# STM32G534xx register map
File version: 1.0
Registers are 32-bit, read-write, reset 0x0 unless marked. A register's access mark holds for its fields unless they carry their own. Offsets are from the block's base; [hi:lo] are bit positions; {n}, {i} and the like mark numbered series; 'fields as' and 'values as' point back to an identical list.

## VREFBUF — Voltage reference buffer (VREFBUF)
Base 0x44007400
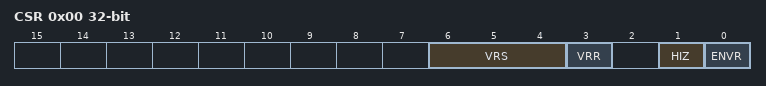
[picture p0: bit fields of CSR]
0x00 CSR — VREFBUF control and status register
  [6:4] VRS — Voltage reference scale
  [3] VRR — Voltage reference buffer ready
  [1] HIZ — High impedance mode
  [0] ENVR — Voltage reference buffer mode enable
0x04 CCR — VREFBUF calibration control register
  [5:0] TRIM — Trimming code

## COMP12_COMMON
Base 0x44008400
Same registers: COMP34_COMMON 0x44008C00, COMP56_COMMON 0x44009400, COMP78_COMMON 0x44009C00
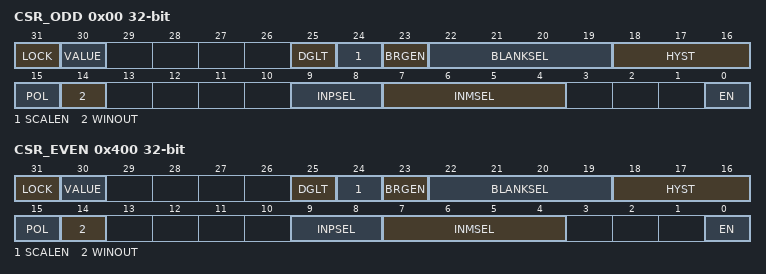
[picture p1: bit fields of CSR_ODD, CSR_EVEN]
0x00 CSR_ODD — COMP control and status register located in register of comparator instance odd, used for bits common to several COMP instances
  [31] LOCK
  [30] VALUE — COMPx output value
  [25] DGLT — DEGLITCHER enable
  [24] SCALEN — VREFINT scaler enable
  [23] BRGEN — VREFINT scaler resistor bridge enable
  [22:19] BLANKSEL — Comparator x blanking signal select
  [18:16] HYST — Comparator x hysteresis
  [15] POL — Comparator x polarity
  [14] WINOUT — COMPx output selector
  [9:8] INPSEL — COMPx channel non-inverting input selection
  [7:4] INMSEL — COMPx channel inverting input selection
  [0] EN — COMPx channel enable
0x400 CSR_EVEN — COMP control and status register located in register of comparator instance even, used for bits common to several COMP instances
  fields as CSR_ODD

## COMP1 — Comparator (COMP)
Base 0x44008400; alternate view of COMP12_COMMON
Same registers: COMP2 0x44008800, COMP3 0x44008C00 (alternate view of COMP34_COMMON), COMP4 0x44009000, COMP5 0x44009400 (alternate view of COMP56_COMMON), COMP6 0x44009800, COMP7 0x44009C00 (alternate view of COMP78_COMMON), COMP8 0x4400A000
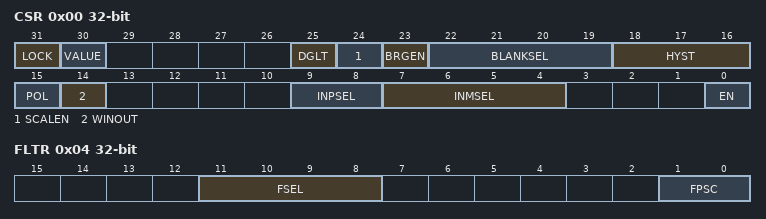
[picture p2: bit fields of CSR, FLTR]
0x00 CSR — Comparator configuration register
  [31] LOCK
  [30] VALUE — COMPx output value
  [25] DGLT — DEGLITCHER enable
  [24] SCALEN — VREFINT scaler enable
  [23] BRGEN — VREFINT scaler resistor bridge enable
  [22:19] BLANKSEL — Comparator x blanking signal select
  [18:16] HYST — Comparator x hysteresis
  [15] POL — Comparator x polarity
  [14] WINOUT — COMPx output selector
  [9:8] INPSEL — COMPx channel non-inverting input selection
  [7:4] INMSEL — COMPx channel inverting input selection
  [0] EN — COMPx channel enable
0x04 FLTR — Comparator filter configuration register
  [11:8] FSEL — COMPx digital filter configuration selection
  [1:0] FPSC — COMPx digital filter configuration selection

## PWR — Power Control (PWR)
Base 0x44020800
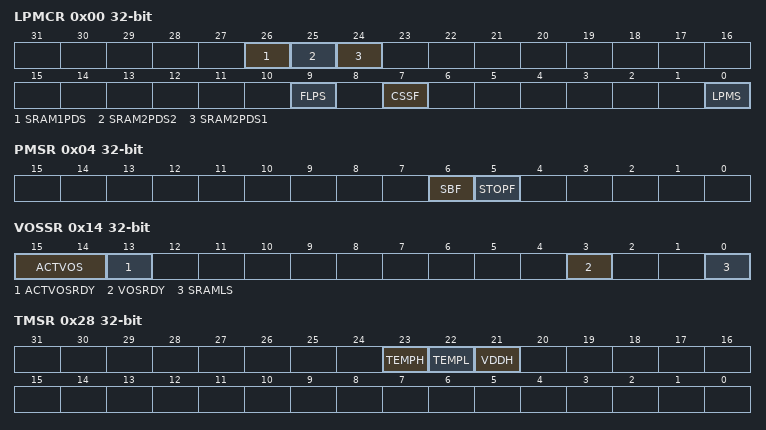
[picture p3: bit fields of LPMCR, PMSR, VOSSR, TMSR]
0x00 LPMCR — PWR low power mode control register
  [26] SRAM1PDS — AHB SRAM1 power-down in Stop mode
  [25] SRAM2PDS2
  [24] SRAM2PDS1
  [9] FLPS
  [7] CSSF
  [0] LPMS — low-power mode selection
0x04 PMSR ro — PWR status register
  [6] SBF — System standby flag
  [5] STOPF — Stop flag
0x10 VOSCR — PWR voltage scaling control register
  [5:4] VOS
0x14 VOSSR ro — PWR voltage scaling status register
  [15:14] ACTVOS — Current voltage scaling range
  [13] ACTVOSRDY — Current VOS voltage level ready
  [3] VOSRDY
  [0] SRAMLS — SRAM memories operation at low speed
0x20 TMCR — PWR tamper monitoring control register
  [1] MONEN
0x24 RTCCR — PWR RTC domain control register
  [0] DRTCP — Disable RTC domain write protection
0x28 TMSR ro — PWR tamper monitoring status register
  [23] TEMPH, [22] TEMPL, [21] VDDH
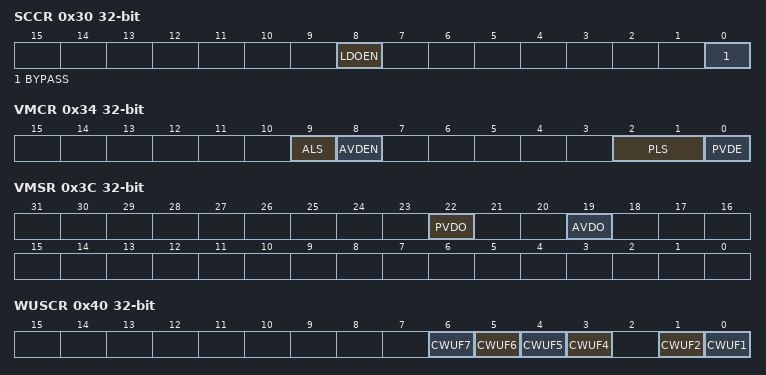
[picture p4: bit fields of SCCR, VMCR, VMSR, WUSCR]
0x30 SCCR — PWR supply configuration control register
  [8] LDOEN — LDO enable
  [0] BYPASS — power management unit bypass
0x34 VMCR — PWR voltage monitor control register
  [9] ALS
  [8] AVDEN
  [2:1] PLS
  [0] PVDE — PVD enable
0x3C VMSR ro — PWR voltage monitor status register
  [22] PVDO — programmable voltage detector output
  [19] AVDO
0x40 WUSCR — PWR wake-up status clear register
  [n-1] CWUF{n} (n=4..7), [1] CWUF2, [0] CWUF1
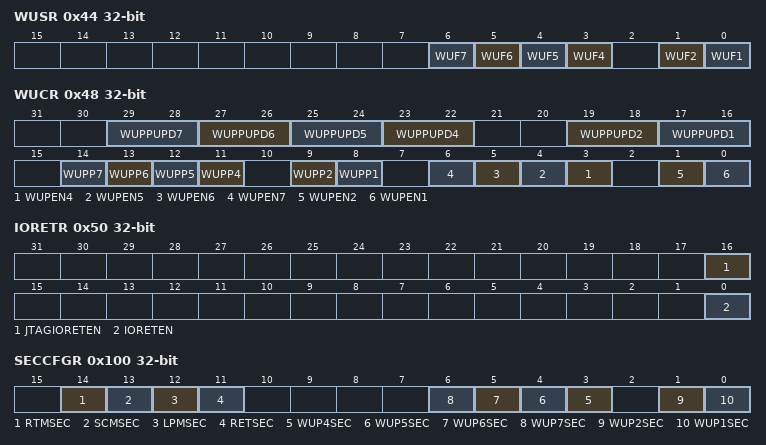
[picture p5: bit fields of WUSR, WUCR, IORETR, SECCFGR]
0x44 WUSR ro — PWR wake-up status register
  [n-1] WUF{n} (n=4..7), [1] WUF2, [0] WUF1
0x48 WUCR — PWR wake-up configuration register
  [2n+15:2n+14] WUPPUPD{n} (n=4..7), [19:18] WUPPUPD2, [17:16] WUPPUPD1, [n+7] WUPP{n} (n=4..7), [9] WUPP2, [8] WUPP1, [n-1] WUPEN{n} (n=4..7), [1] WUPEN2, [0] WUPEN1
0x50 IORETR — PWR I/O retention register
  [16] JTAGIORETEN — JTAG IOs retention enable
  [0] IORETEN — IO retention enable
0x100 SECCFGR — PWR security configuration register
  [14] RTMSEC
  [13] SCMSEC
  [12] LPMSEC — low-power modes secure protection
  [11] RETSEC — retention secure protection
  [n-1] WUP{n}SEC (n=4..7)
  [1] WUP2SEC
  [0] WUP1SEC
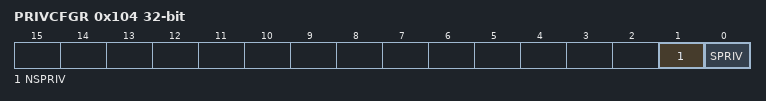
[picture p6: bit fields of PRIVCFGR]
0x104 PRIVCFGR — PWR privilege configuration register
  [1] NSPRIV, [0] SPRIV
